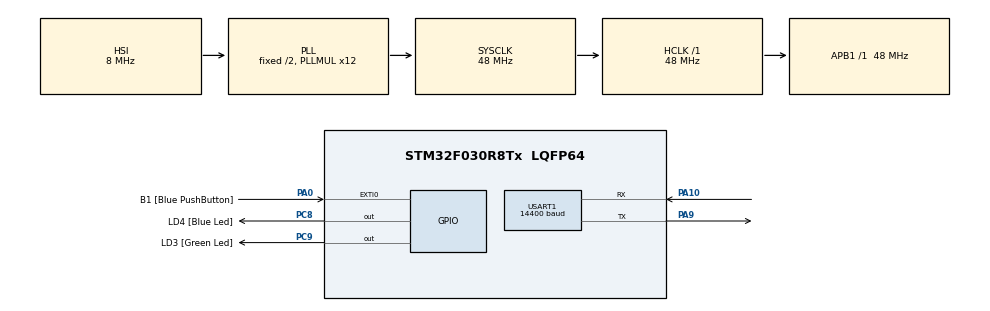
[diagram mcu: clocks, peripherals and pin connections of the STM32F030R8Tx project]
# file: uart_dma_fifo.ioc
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Dma.Request0=USART1_RX
Dma.Request1=USART1_TX
Dma.USART1_RX.0.Direction=DMA_PERIPH_TO_MEMORY
Dma.USART1_RX.0.Instance=DMA1_Channel3
Dma.USART1_RX.0.MemDataAlignment=DMA_MDATAALIGN_WORD
Dma.USART1_RX.0.MemInc=DMA_MINC_DISABLE
Dma.USART1_RX.0.Mode=DMA_CIRCULAR
Dma.USART1_RX.0.PeriphDataAlignment=DMA_PDATAALIGN_WORD
Dma.USART1_RX.0.PeriphInc=DMA_PINC_DISABLE
Dma.USART1_RX.0.Priority=DMA_PRIORITY_HIGH
Dma.USART1_TX.1.Direction=DMA_MEMORY_TO_PERIPH
Dma.USART1_TX.1.Instance=DMA1_Channel2
Dma.USART1_TX.1.MemDataAlignment=DMA_MDATAALIGN_WORD
Dma.USART1_TX.1.MemInc=DMA_MINC_DISABLE
Dma.USART1_TX.1.Mode=DMA_CIRCULAR
Dma.USART1_TX.1.PeriphDataAlignment=DMA_PDATAALIGN_WORD
Dma.USART1_TX.1.PeriphInc=DMA_PINC_DISABLE
Dma.USART1_TX.1.Priority=DMA_PRIORITY_HIGH
Mcu.Family=STM32F0
Mcu.Name=STM32F030R8Tx
Mcu.Package=LQFP64
NVIC.DMA1_Channel2_3_IRQn=true\:0\:0\:false
NVIC.USART1_IRQn=true\:0\:0\:false
PA0.GPIO_Label=B1 [Blue PushButton]
PA0.GPIO_ModeDefaultEXTI=GPIO_MODE_EVT_RISING
PA0.GPIO_PuPd=GPIO_NOPULL
PA0.Signal=GPXTI0
PA10.Mode=Asynchronous
PA10.Signal=USART1_RX
PA13.GPIO_Label=SWDIO
PA13.Mode=Serial-WireDebug
PA13.Signal=SYS_SWDIO
PA14.GPIO_Label=SWCLK
PA14.Mode=Serial-WireDebug
PA14.Signal=SYS_SWCLK
PA9.Mode=Asynchronous
PA9.Signal=USART1_TX
PC8.GPIO_Label=LD4 [Blue Led]
PC8.GPIO_ModeDefaultOutputPP=GPIO_MODE_OUTPUT_PP
PC8.GPIO_PuPd=GPIO_NOPULL
PC8.GPIO_Speed=GPIO_SPEED_LOW
PC8.Signal=GPIO_Output
PC9.GPIO_Label=LD3 [Green Led]
PC9.GPIO_ModeDefaultOutputPP=GPIO_MODE_OUTPUT_PP
PC9.GPIO_PuPd=GPIO_NOPULL
PC9.GPIO_Speed=GPIO_SPEED_LOW
PC9.Signal=GPIO_Output
ProjectManager.TargetToolchain=MDK-ARM V5
RCC.AHBFreq_Value=48000000
RCC.APB1Freq_Value=48000000
RCC.APB1TimFreq_Value=48000000
RCC.HCLKFreq_Value=48000000
RCC.PLLMUL=RCC_PLL_MUL12
RCC.SYSCLKFreq_VALUE=48000000
RCC.SYSCLKSource=RCC_SYSCLKSOURCE_PLLCLK
USART1.BaudRate=14400

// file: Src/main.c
/**
  ******************************************************************************
  * File Name          : main.c
  * Date               : 05/11/2015 21:48:26
  * Description        : Main program body
  ******************************************************************************
  *
  * COPYRIGHT(c) 2015 STMicroelectronics
  *
  * Redistribution and use in source and binary forms, with or without modification,
  * are permitted provided that the following conditions are met:
  *   1. Redistributions of source code must retain the above copyright notice,
  *      this list of conditions and the following disclaimer.
  *   2. Redistributions in binary form must reproduce the above copyright notice,
  *      this list of conditions and the following disclaimer in the documentation
  *      and/or other materials provided with the distribution.
  *   3. Neither the name of STMicroelectronics nor the names of its contributors
  *      may be used to endorse or promote products derived from this software
  *      without specific prior written permission.
  *
  * THIS SOFTWARE IS PROVIDED BY THE COPYRIGHT HOLDERS AND CONTRIBUTORS "AS IS"
  * AND ANY EXPRESS OR IMPLIED WARRANTIES, INCLUDING, BUT NOT LIMITED TO, THE
  * IMPLIED WARRANTIES OF MERCHANTABILITY AND FITNESS FOR A PARTICULAR PURPOSE ARE
  * DISCLAIMED. IN NO EVENT SHALL THE COPYRIGHT HOLDER OR CONTRIBUTORS BE LIABLE
  * FOR ANY DIRECT, INDIRECT, INCIDENTAL, SPECIAL, EXEMPLARY, OR CONSEQUENTIAL
  * DAMAGES (INCLUDING, BUT NOT LIMITED TO, PROCUREMENT OF SUBSTITUTE GOODS OR
  * SERVICES; LOSS OF USE, DATA, OR PROFITS; OR BUSINESS INTERRUPTION) HOWEVER
  * CAUSED AND ON ANY THEORY OF LIABILITY, WHETHER IN CONTRACT, STRICT LIABILITY,
  * OR TORT (INCLUDING NEGLIGENCE OR OTHERWISE) ARISING IN ANY WAY OUT OF THE USE
  * OF THIS SOFTWARE, EVEN IF ADVISED OF THE POSSIBILITY OF SUCH DAMAGE.
  *
  ******************************************************************************
  */

#include "stm32f0xx_hal.h"
#include "stdio.h"
#include "stdlib.h"
#include "string.h"
#define MAXCLISTRING 100
/* USER CODE BEGIN Includes */
uint8_t rxBuffer = '\000';
uint8_t rxString[MAXCLISTRING];
int rxindex = 0;
uint8_t txBuffer ='t';
uint8_t txString[MAXCLISTRING];
int txindex=0;
/* USER CODE END Includes */

UART_HandleTypeDef huart1;
DMA_HandleTypeDef hdma_usart1_rx;
DMA_HandleTypeDef hdma_usart1_tx;

void SystemClock_Config(void);
static void MX_GPIO_Init(void);
static void MX_DMA_Init(void);
static void MX_USART1_UART_Init(void);
extern DMA_HandleTypeDef hdma_usart1_rx;
extern DMA_HandleTypeDef hdma_usart1_tx;
void print(char string[]);

int main(void)
{

  /* MCU Configuration----------------------------------------------------------*/

  /* Reset of all peripherals, Initializes the Flash interface and the Systick. */
  HAL_Init();

  /* Configure the system clock */
  SystemClock_Config();

  /* Initialize all configured peripherals */
  MX_GPIO_Init();
  MX_DMA_Init();
  MX_USART1_UART_Init();
	HAL_UART_Receive_DMA(&huart1,&rxBuffer,1);

  /* Infinite loop */
  while (1)
  {
  }

}

/** System Clock Configuration
*/
void SystemClock_Config(void)
{

  RCC_OscInitTypeDef RCC_OscInitStruct;
  RCC_ClkInitTypeDef RCC_ClkInitStruct;
  RCC_PeriphCLKInitTypeDef PeriphClkInit;

  RCC_OscInitStruct.OscillatorType = RCC_OSCILLATORTYPE_HSI;
  RCC_OscInitStruct.HSIState = RCC_HSI_ON;
  RCC_OscInitStruct.HSICalibrationValue = 16;
  RCC_OscInitStruct.PLL.PLLState = RCC_PLL_ON;
  RCC_OscInitStruct.PLL.PLLSource = RCC_PLLSOURCE_HSI;
  RCC_OscInitStruct.PLL.PLLMUL = RCC_PLL_MUL12;
  RCC_OscInitStruct.PLL.PREDIV = RCC_PREDIV_DIV1;
  HAL_RCC_OscConfig(&RCC_OscInitStruct);

  RCC_ClkInitStruct.ClockType = RCC_CLOCKTYPE_SYSCLK;
  RCC_ClkInitStruct.SYSCLKSource = RCC_SYSCLKSOURCE_PLLCLK;
  RCC_ClkInitStruct.AHBCLKDivider = RCC_SYSCLK_DIV1;
  RCC_ClkInitStruct.APB1CLKDivider = RCC_HCLK_DIV1;
  HAL_RCC_ClockConfig(&RCC_ClkInitStruct, FLASH_LATENCY_1);

  PeriphClkInit.PeriphClockSelection = RCC_PERIPHCLK_USART1;
  PeriphClkInit.Usart1ClockSelection = RCC_USART1CLKSOURCE_PCLK1;
  HAL_RCCEx_PeriphCLKConfig(&PeriphClkInit);

  __SYSCFG_CLK_ENABLE();

}

/* USART1 init function */
void MX_USART1_UART_Init(void)
{

  huart1.Instance = USART1;
  huart1.Init.BaudRate = 14400;
  huart1.Init.WordLength = UART_WORDLENGTH_8B;
  huart1.Init.StopBits = UART_STOPBITS_1;
  huart1.Init.Parity = UART_PARITY_NONE;
  huart1.Init.Mode = UART_MODE_TX_RX;
  huart1.Init.HwFlowCtl = UART_HWCONTROL_NONE;
  huart1.Init.OverSampling = UART_OVERSAMPLING_16;
  huart1.Init.OneBitSampling = UART_ONEBIT_SAMPLING_DISABLED ;
  huart1.AdvancedInit.AdvFeatureInit = UART_ADVFEATURE_NO_INIT;
  HAL_UART_Init(&huart1);

}

void MX_DMA_Init(void)
{
	__DMA1_CLK_ENABLE();
	extern DMA_HandleTypeDef hdma_usart1_rx;
	extern DMA_HandleTypeDef hdma_usart1_tx;

	hdma_usart1_rx.Instance=DMA1_Channel3;
	hdma_usart1_rx.Init.Direction=DMA_PERIPH_TO_MEMORY;
	hdma_usart1_rx.Init.PeriphInc=DMA_PINC_DISABLE;
	hdma_usart1_rx.Init.MemInc=DMA_MINC_DISABLE;
	hdma_usart1_rx.Init.PeriphDataAlignment=DMA_PDATAALIGN_WORD;
	hdma_usart1_rx.Init.MemDataAlignment=DMA_MDATAALIGN_WORD;
	hdma_usart1_rx.Init.Mode=DMA_CIRCULAR;
	hdma_usart1_rx.Init.Priority=DMA_PRIORITY_HIGH;
	//hdma_usart1_rx.Init.FIFOMode=DMA_FIFOMODE_ENABLE;
	HAL_DMA_Init(&hdma_usart1_rx);
	__HAL_LINKDMA(&huart1,hdmarx,hdma_usart1_rx);

	hdma_usart1_tx.Instance=DMA1_Channel2;
	hdma_usart1_tx.Init.Direction=DMA_MEMORY_TO_PERIPH;
	hdma_usart1_tx.Init.PeriphInc=DMA_PINC_DISABLE;
	hdma_usart1_tx.Init.MemInc=DMA_MINC_DISABLE;
	hdma_usart1_tx.Init.PeriphDataAlignment=DMA_PDATAALIGN_WORD;
	hdma_usart1_tx.Init.MemDataAlignment=DMA_MDATAALIGN_WORD;
	hdma_usart1_tx.Init.Mode=DMA_CIRCULAR;
	hdma_usart1_tx.Init.Priority=DMA_PRIORITY_HIGH;

	HAL_DMA_Init(&hdma_usart1_tx);
	__HAL_LINKDMA(&huart1,hdmatx,hdma_usart1_tx);

  /* DMA controller clock enable */

  /* DMA interrupt init */
  HAL_NVIC_SetPriority(DMA1_Channel2_3_IRQn, 0, 0);
  HAL_NVIC_EnableIRQ(DMA1_Channel2_3_IRQn);
}
void DMA1_Channel2_3_IRQnHandler(void){
	HAL_NVIC_ClearPendingIRQ(DMA1_Channel2_3_IRQn);
	HAL_DMA_IRQHandler(&hdma_usart1_rx);
}
/** Configure pins as
        * Analog
        * Input
        * Output
        * EVENT_OUT
        * EXTI
*/
void MX_GPIO_Init(void)
{

  GPIO_InitTypeDef GPIO_InitStruct;

  /* GPIO Ports Clock Enable */
  __GPIOA_CLK_ENABLE();
  __GPIOC_CLK_ENABLE();

  /*Configure GPIO pin : PA0 */
  GPIO_InitStruct.Pin = GPIO_PIN_0;
  GPIO_InitStruct.Mode = GPIO_MODE_EVT_RISING;
  GPIO_InitStruct.Pull = GPIO_NOPULL;
  HAL_GPIO_Init(GPIOA, &GPIO_InitStruct);

  /*Configure GPIO pins : PC8 PC9 */
  GPIO_InitStruct.Pin = GPIO_PIN_8|GPIO_PIN_9;
  GPIO_InitStruct.Mode = GPIO_MODE_OUTPUT_PP;
  GPIO_InitStruct.Pull = GPIO_NOPULL;
  GPIO_InitStruct.Speed = GPIO_SPEED_LOW;
  HAL_GPIO_Init(GPIOC, &GPIO_InitStruct);

}
void print(char string[]){
	HAL_UART_Transmit(&huart1,(uint8_t *)&string,strlen(string),5);
}

void HAL_UART_RxCpltCallback(UART_HandleTypeDef *huart)
{
    //__HAL_UART_FLUSH_DRREGISTER(&huart1); // Clear the buffer to prevent overrun

    int i = 0;

    print(&rxBuffer); // Echo the character that caused this callback so the user can see what they are typing

    if (rxBuffer == 8 || rxBuffer == 127) // If Backspace or del
    {
        print(" \b"); // "\b space \b" clears the terminal character. Remember we just echoced a \b so don't need another one here, just space and \b
        rxindex--;
        if (rxindex < 0) rxindex = 0;
    }

    else if (rxBuffer == '\n' || rxBuffer == '\r') // If Enter
    {
				print("transfer tamam");
        rxString[rxindex] = 0;
        rxindex = 0;
        for (i = 0; i < MAXCLISTRING; i++) rxString[i] = 0; // Clear the string buffer
    }

    else
    {
        rxString[rxindex] = rxBuffer; // Add that character to the string
        rxindex++;
        if (rxindex > MAXCLISTRING) // User typing too much, we can't have commands that big
        {
            rxindex = 0;
            for (i = 0; i < MAXCLISTRING; i++) rxString[i] = 0; // Clear the string buffer
            print("\r\nConsole> ");
        }
    }
}
void HAL_UART_TxCpltCallback(UART_HandleTypeDef *huart){
	HAL_GPIO_WritePin(GPIOC,GPIO_PIN_8,GPIO_PIN_SET);
	HAL_Delay(100);
	HAL_GPIO_WritePin(GPIOC,GPIO_PIN_8,GPIO_PIN_RESET);
}

/************************ (C) COPYRIGHT STMicroelectronics *****END OF FILE****/
